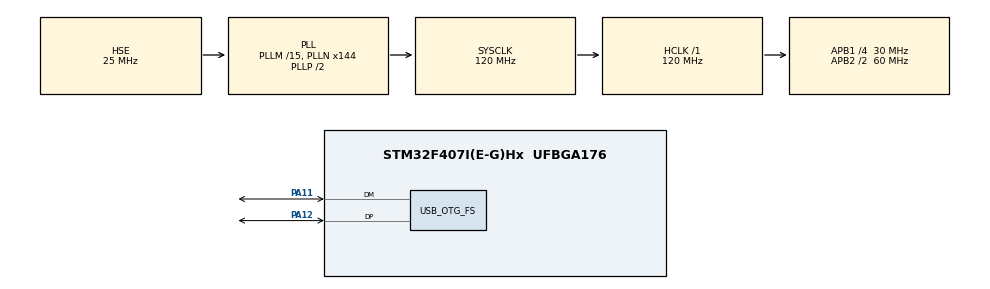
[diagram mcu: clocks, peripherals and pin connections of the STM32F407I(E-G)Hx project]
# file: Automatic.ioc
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Mcu.Family=STM32F4
Mcu.Name=STM32F407I(E-G)Hx
Mcu.Package=UFBGA176
NVIC.OTG_FS_IRQn=true\:0\:0\:false\:false\:true\:false\:true\:true
NVIC.PriorityGroup=NVIC_PRIORITYGROUP_4
PA11.Mode=Device_Only
PA11.Signal=USB_OTG_FS_DM
PA12.Mode=Device_Only
PA12.Signal=USB_OTG_FS_DP
PA13.Mode=Serial_Wire
PA13.Signal=SYS_JTMS-SWDIO
PA14.Mode=Serial_Wire
PA14.Signal=SYS_JTCK-SWCLK
PH0-OSC_IN.Mode=HSE-External-Oscillator
PH0-OSC_IN.Signal=RCC_OSC_IN
PH1-OSC_OUT.Mode=HSE-External-Oscillator
PH1-OSC_OUT.Signal=RCC_OSC_OUT
ProjectManager.HeapSize=0x200
ProjectManager.StackSize=0x400
ProjectManager.TargetToolchain=MDK-ARM V5.32
RCC.48MHZClocksFreq_Value=48000000
RCC.AHBFreq_Value=120000000
RCC.APB1CLKDivider=RCC_HCLK_DIV4
RCC.APB1Freq_Value=30000000
RCC.APB1TimFreq_Value=60000000
RCC.APB2CLKDivider=RCC_HCLK_DIV2
RCC.APB2Freq_Value=60000000
RCC.APB2TimFreq_Value=120000000
RCC.CortexFreq_Value=120000000
RCC.HCLKFreq_Value=120000000
RCC.HSE_VALUE=25000000
RCC.HSI_VALUE=16000000
RCC.LSE_VALUE=32768
RCC.PLLM=15
RCC.PLLN=144
RCC.PLLQ=5
RCC.SYSCLKFreq_VALUE=120000000
RCC.SYSCLKSource=RCC_SYSCLKSOURCE_PLLCLK
RCC.VCOOutputFreq_Value=240000000
USB_DEVICE.CLASS_NAME_FS=CDC
USB_DEVICE.VirtualMode-CDC_FS=Cdc
USB_DEVICE.VirtualModeFS=Cdc_FS
USB_OTG_FS.VirtualMode=Device_Only
VP_USB_DEVICE_VS_USB_DEVICE_CDC_FS.Mode=CDC_FS
board=custom

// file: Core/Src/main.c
/* USER CODE BEGIN Header */
/**
  ******************************************************************************
  * @file           : main.c
  * @brief          : Main program body
  ******************************************************************************
  * @attention
  *
  * Copyright (c) 2026 STMicroelectronics.
  * All rights reserved.
  *
  * This software is licensed under terms that can be found in the LICENSE file
  * in the root directory of this software component.
  * If no LICENSE file comes with this software, it is provided AS-IS.
  *
  ******************************************************************************
  */
/* USER CODE END Header */
#include "main.h"
#include "usb_device.h"
#include "gpio.h"

/* USER CODE BEGIN Includes */
#include "vision.h"
/* USER CODE END Includes */

void SystemClock_Config(void);

int main(void)
{

  /* MCU Configuration--------------------------------------------------------*/

  /* Reset of all peripherals, Initializes the Flash interface and the Systick. */
  HAL_Init();

  /* Configure the system clock */
  SystemClock_Config();

  /* Initialize all configured peripherals */
  MX_GPIO_Init();
  MX_USB_DEVICE_Init();
  /* USER CODE BEGIN 2 */
  vision_init();
  /* USER CODE END 2 */

  /* Infinite loop */
  /* USER CODE BEGIN WHILE */
  while (1)
  {
    vision_task();
    /* USER CODE END WHILE */

  }
}

void SystemClock_Config(void)
{
  RCC_OscInitTypeDef RCC_OscInitStruct = {0};
  RCC_ClkInitTypeDef RCC_ClkInitStruct = {0};

  /** Configure the main internal regulator output voltage
  */
  __HAL_RCC_PWR_CLK_ENABLE();
  __HAL_PWR_VOLTAGESCALING_CONFIG(PWR_REGULATOR_VOLTAGE_SCALE1);

  /** Initializes the RCC Oscillators according to the specified parameters
  * in the RCC_OscInitTypeDef structure.
  */
  RCC_OscInitStruct.OscillatorType = RCC_OSCILLATORTYPE_HSE;
  RCC_OscInitStruct.HSEState = RCC_HSE_ON;
  RCC_OscInitStruct.PLL.PLLState = RCC_PLL_ON;
  RCC_OscInitStruct.PLL.PLLSource = RCC_PLLSOURCE_HSE;
  RCC_OscInitStruct.PLL.PLLM = 15;
  RCC_OscInitStruct.PLL.PLLN = 144;
  RCC_OscInitStruct.PLL.PLLP = RCC_PLLP_DIV2;
  RCC_OscInitStruct.PLL.PLLQ = 5;
  if (HAL_RCC_OscConfig(&RCC_OscInitStruct) != HAL_OK)
  {
    Error_Handler();
  }

  /** Initializes the CPU, AHB and APB buses clocks
  */
  RCC_ClkInitStruct.ClockType = RCC_CLOCKTYPE_HCLK|RCC_CLOCKTYPE_SYSCLK
                              |RCC_CLOCKTYPE_PCLK1|RCC_CLOCKTYPE_PCLK2;
  RCC_ClkInitStruct.SYSCLKSource = RCC_SYSCLKSOURCE_PLLCLK;
  RCC_ClkInitStruct.AHBCLKDivider = RCC_SYSCLK_DIV1;
  RCC_ClkInitStruct.APB1CLKDivider = RCC_HCLK_DIV4;
  RCC_ClkInitStruct.APB2CLKDivider = RCC_HCLK_DIV2;

  if (HAL_RCC_ClockConfig(&RCC_ClkInitStruct, FLASH_LATENCY_3) != HAL_OK)
  {
    Error_Handler();
  }
}

void Error_Handler(void)
{
  __disable_irq();
  while (1)
  {
  }
}
